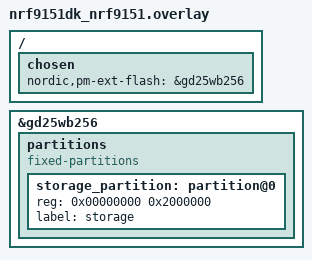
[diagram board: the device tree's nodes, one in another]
/ {
	/* Configure partition manager to use gd25wb256 as the external flash */
	chosen {
		nordic,pm-ext-flash = &gd25wb256;
	};
};

/delete-node/ &storage_partition;

&gd25wb256 {
	status = "okay";
	partitions {
		compatible = "fixed-partitions";
		#address-cells = <1>;
		#size-cells = <1>;

		storage_partition: partition@0 {
			reg = <0x00000000 0x2000000>;
			label = "storage";
		};
	};
};
